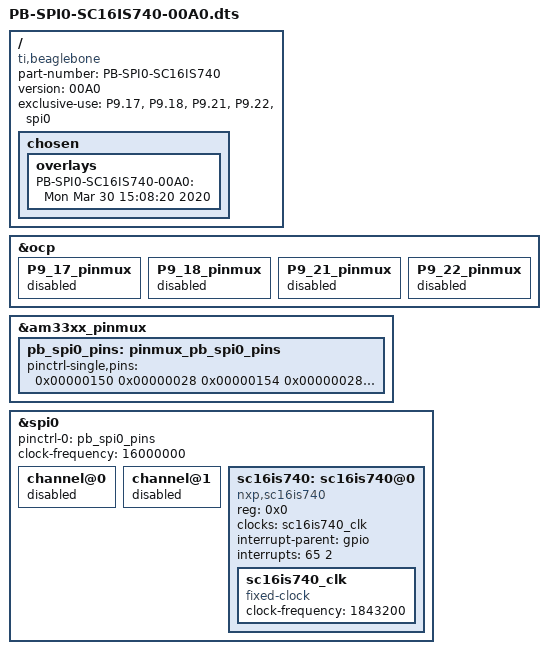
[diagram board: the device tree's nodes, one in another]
/*
 * Copyright (C) 2017 Robert Nelson <robertcnelson@gmail.com>
 *
 * This program is free software; you can redistribute it and/or modify
 * it under the terms of the GNU General Public License version 2 as
 * published by the Free Software Foundation.
 *
 * https://www.mikroe.com/eth-click
 * https://download.mikroe.com/documents/add-on-boards/click/eth/eth-click-manual-v100.pdf
 */

/dts-v1/;
/plugin/;

// #include <dt-bindings/gpio/gpio.h>
// #include <dt-bindings/pinctrl/am33xx.h>
// #include <dt-bindings/interrupt-controller/irq.h>

/ {
	compatible = "ti,beaglebone", "ti,beaglebone-black", "ti,beaglebone-green";

	/* identification */
	part-number = "PB-SPI0-SC16IS740";
	version = "00A0";

	/* state the resources this cape uses */
	exclusive-use =
		/* the pin header uses */
		"P9.17",	/* P9_17 (A16) spi0_cs0.spi0_cs0 */
		"P9.18",	/* P9_18 (B16) spi0_d1.spi0_d1 */
		"P9.21",	/* P9_21 (B17) spi0_d0.spi0_d0 */
		"P9.22",	/* P9_22 (A17) spi0_sclk.spi0_sclk */
		/* the hardware ip uses */
		"spi0";

	// SPI0_CS -> P9_17 ( PIN_OUTPUT ) MODE0.
	// SPI0_D1 -> P9_18 ( PIN_OUTPUT ) MODE0.
	// SPI0_D0 -> P9_21 ( PIN_INPUT ) MODE0.
	// SPI0_SCLK -> P9_22 ( PIN_OUTPUT ) MODE0.

	/*
	 * Helper to show loaded overlays under: /proc/device-tree/chosen/overlays/
	 */
	fragment@0 {
		target-path="/";
		__overlay__ {

			chosen {
				overlays {
					PB-SPI0-SC16IS740-00A0 = "Mon Mar 30 15:08:20 2020";
				};
			};
		};
	};

	/*
	 * Free up the pins used by the cape from the pinmux helpers.
	 */
	fragment@1 {
		target = <&ocp>;
		__overlay__ {
			P9_17_pinmux { status = "disabled"; };	/* P9_17 (A16) spi0_cs0.spi0_cs0 */
			P9_18_pinmux { status = "disabled"; };	/* P9_18 (B16) spi0_d1.spi0_d1 */
			P9_21_pinmux { status = "disabled"; };	/* P9_21 (B17) spi0_d0.spi0_d0 */
			P9_22_pinmux { status = "disabled"; };	/* P9_22 (A17) spi0_sclk.spi0_sclk */
		};
	};

	fragment@2 {
		target = <&am33xx_pinmux>;
		__overlay__ {
			pb_spi0_pins: pinmux_pb_spi0_pins {
				pinctrl-single,pins = <0x00000150 0x00000028 0x00000154 0x00000028 0x00000158 0x00000028 0x0000015c 0x00000028>;
				// pinctrl-single,pins = <
				//	AM33XX_IOPAD(0x0950, PIN_INPUT | MUX_MODE0 ) /* P9_22 (A17) spi0_sclk.spi0_sclk */
				//	AM33XX_IOPAD(0x0954, PIN_INPUT | MUX_MODE0 ) /* P9_21 (B17) spi0_d0.spi0_d0 */
				//	AM33XX_IOPAD(0x0958, PIN_INPUT | MUX_MODE0 ) /* P9_18 (B16) spi0_d1.spi0_d1 */
				//	AM33XX_IOPAD(0x095c, PIN_INPUT | MUX_MODE0 ) /* P9_17 (A16) spi0_cs0.spi0_cs0 */
				// >;
			};
		};
	};

	fragment@3 {
		target = <&spi0>;
		__overlay__ {
			status = "okay";
			pinctrl-names = "default";
			pinctrl-0 = <&pb_spi0_pins>;

			/* this is the configuration part */
			clock-frequency = <16000000>;

			channel@0{ status = "disabled"; };
			channel@1{ status = "disabled"; };
		};
	};

	fragment@4 {
		target = <&spi0>;
		__overlay__ {
			#address-cells = <1>;
			#size-cells = <0>;
			status = "okay";

			sc16is740: sc16is740@0 {
				compatible = "nxp,sc16is740";
				reg = <0x0>; /* address */
				clocks = <&sc16is740_clk>;
				interrupt-parent = <&gpio>;
				interrupts = <65 2>; /* IRQ_TYPE_FALLING_EDGE */
				#gpio-cells = <2>;

				sc16is740_clk: sc16is740_clk {
					compatible = "fixed-clock";
					#clock-cells = <0>;
					clock-frequency = <1843200>;
				};
			};
		};
	};
};
